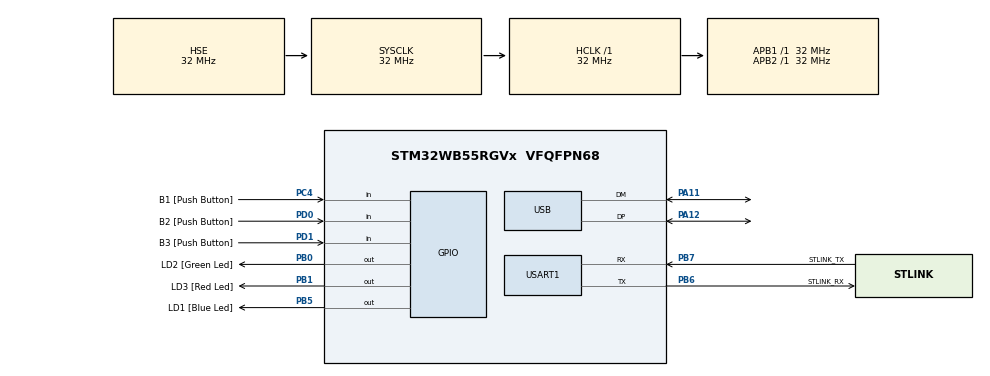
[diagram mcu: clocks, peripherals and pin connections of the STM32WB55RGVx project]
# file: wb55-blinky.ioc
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Mcu.Family=STM32WB
RCC.CortexFreq_Value=32000000
RCC.SMPSCLockSelectionVirtualVirtual=RCC_SMPSCLKSOURCE_HSI
USART1.WordLength=WORDLENGTH_7B
PA14.GPIO_Label=JTCK
PD0.GPIO_Label=B2 [Push Button]
PA11.Mode=Device
PB0.GPIO_Label=LD2 [Green Led]
PB6.GPIO_Label=STLINK_RX
RCC.SYSCLKSource=RCC_SYSCLKSOURCE_HSE
ProjectManager.StackSize=0x400
PA12.Signal=USB_DP
RCC.HCLKFreq_Value=32000000
RCC.APB2TimFreq_Value=32000000
PB6.Signal=USART1_TX
PB6.Mode=Asynchronous
PD0.Signal=GPIO_Input
OSC_OUT.Mode=HSE-External-Oscillator
OSC_OUT.Signal=RCC_OSC_OUT
RCC.AHBFreq_Value=32000000
RCC.HSE_VALUE=32000000
PB3.Mode=Trace_Asynchronous_SW
PD1.GPIO_Label=B3 [Push Button]
PC14-OSC32_IN.Mode=LSE-External-Oscillator
PC4.GPIO_Label=B1 [Push Button]
PA14.Mode=Trace_Asynchronous_SW
PB1.GPIO_Label=LD3 [Red Led]
PB7.Signal=USART1_RX
RCC.APB3Freq_Value=16000000
PB7.GPIO_Label=STLINK_TX
Mcu.Package=VFQFPN68
PB1.Signal=GPIO_Output
PB5.GPIO_Label=LD1 [Blue Led]
RCC.APB1TimFreq_Value=32000000
RCC.SMPSDivider=1
RCC.HSI48_VALUE=48000000
RCC.PLLSAI1N=24
PB3.GPIO_Label=JTDO
PB7.GPIO_PuPd=GPIO_PULLUP
PC15-OSC32_OUT.Mode=LSE-External-Oscillator
PC13.Signal=SYS_WKUP2
PB6.GPIO_PuPd=GPIO_PULLUP
PC4.Signal=GPIO_Input
PD1.Signal=GPIO_Input
PC14-OSC32_IN.Signal=RCC_OSC32_IN
USART1.VirtualMode-Asynchronous=VM_ASYNC
PA13.Signal=SYS_JTMS-SWDIO
ProjectManager.TargetToolchain=SW4STM32
OSC_IN.Signal=RCC_OSC_IN
RCC.USBFreq_Value=48000000
PC15-OSC32_OUT.Signal=RCC_OSC32_OUT
RCC.SMPSCLockSelectionVirtual=RCC_SMPSCLKSOURCE_HSI
board=P-NUCLEO-WB55-Nucleo
RCC.VCOOutputFreq_Value=128000000
RCC.APB2Freq_Value=32000000
RCC.ADCFreq_Value=48000000
PA13.Mode=Trace_Asynchronous_SW
PC13.Mode=SYS_WakeUp1
Mcu.Name=STM32WB55RGVx
PA13.GPIO_Label=JTMS
PB3.Signal=SYS_JTDO-SWO
RCC.SYSCLKFreq_VALUE=32000000
PB5.Signal=GPIO_Output
PA12.Mode=Device
OSC_IN.Mode=HSE-External-Oscillator
PB7.Mode=Asynchronous
PA11.Signal=USB_DM
PA14.Signal=SYS_JTCK-SWCLK
ProjectManager.HeapSize=0x200
RCC.HSI_VALUE=16000000
NVIC.PriorityGroup=NVIC_PRIORITYGROUP_4
RCC.PLLN=32
RCC.APB1Freq_Value=32000000
PB0.Signal=GPIO_Output

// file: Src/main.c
/* USER CODE BEGIN Header */
/**
  ******************************************************************************
  * @file           : main.c
  * @brief          : Main program body
  ******************************************************************************
  * @attention
  *
  * <h2><center>&copy; Copyright (c) 2020 STMicroelectronics.
  * All rights reserved.</center></h2>
  *
  * This software component is licensed by ST under BSD 3-Clause license,
  * the "License"; You may not use this file except in compliance with the
  * License. You may obtain a copy of the License at:
  *                        opensource.org/licenses/BSD-3-Clause
  *
  ******************************************************************************
  */
/* USER CODE END Header */

#include "main.h"

UART_HandleTypeDef huart1;

PCD_HandleTypeDef hpcd_USB_FS;

void SystemClock_Config(void);
static void MX_GPIO_Init(void);
static void MX_USART1_UART_Init(void);
static void MX_USB_PCD_Init(void);

int main(void)
{

  /* MCU Configuration--------------------------------------------------------*/

  /* Reset of all peripherals, Initializes the Flash interface and the Systick. */
  HAL_Init();

  /* Configure the system clock */
  SystemClock_Config();

  /* Initialize all configured peripherals */
  MX_GPIO_Init();
  MX_USART1_UART_Init();
  MX_USB_PCD_Init();

  /* Infinite loop */
  /* USER CODE BEGIN WHILE */
#pragma clang diagnostic push
#pragma ide diagnostic ignored "EndlessLoop"
  while (1)
  {
    HAL_GPIO_WritePin(GPIOB, LD2_Pin, GPIO_PIN_SET);
    HAL_Delay(500);
    HAL_GPIO_WritePin(GPIOB, LD2_Pin, GPIO_PIN_RESET);
    HAL_Delay(500);

    /* USER CODE END WHILE */

    /* USER CODE BEGIN 3 */
  }
#pragma clang diagnostic pop
  /* USER CODE END 3 */
}

void SystemClock_Config(void)
{
  RCC_OscInitTypeDef RCC_OscInitStruct = {0};
  RCC_ClkInitTypeDef RCC_ClkInitStruct = {0};
  RCC_PeriphCLKInitTypeDef PeriphClkInitStruct = {0};

  /** Macro to configure the PLL multiplication factor
  */
  __HAL_RCC_PLL_PLLM_CONFIG(RCC_PLLM_DIV1);
  /** Macro to configure the PLL clock source
  */
  __HAL_RCC_PLL_PLLSOURCE_CONFIG(RCC_PLLSOURCE_MSI);
  /** Configure LSE Drive Capability
  */
  HAL_PWR_EnableBkUpAccess();
  __HAL_RCC_LSEDRIVE_CONFIG(RCC_LSEDRIVE_LOW);
  /** Configure the main internal regulator output voltage
  */
  __HAL_PWR_VOLTAGESCALING_CONFIG(PWR_REGULATOR_VOLTAGE_SCALE1);
  /** Initializes the CPU, AHB and APB busses clocks
  */
  RCC_OscInitStruct.OscillatorType = RCC_OSCILLATORTYPE_HSI|RCC_OSCILLATORTYPE_HSE
                              |RCC_OSCILLATORTYPE_LSE|RCC_OSCILLATORTYPE_MSI;
  RCC_OscInitStruct.HSEState = RCC_HSE_ON;
  RCC_OscInitStruct.LSEState = RCC_LSE_ON;
  RCC_OscInitStruct.HSIState = RCC_HSI_ON;
  RCC_OscInitStruct.MSIState = RCC_MSI_ON;
  RCC_OscInitStruct.HSICalibrationValue = RCC_HSICALIBRATION_DEFAULT;
  RCC_OscInitStruct.MSICalibrationValue = RCC_MSICALIBRATION_DEFAULT;
  RCC_OscInitStruct.MSIClockRange = RCC_MSIRANGE_6;
  RCC_OscInitStruct.PLL.PLLState = RCC_PLL_NONE;
  if (HAL_RCC_OscConfig(&RCC_OscInitStruct) != HAL_OK)
  {
    Error_Handler();
  }
  /** Configure the SYSCLKSource, HCLK, PCLK1 and PCLK2 clocks dividers
  */
  RCC_ClkInitStruct.ClockType = RCC_CLOCKTYPE_HCLK4|RCC_CLOCKTYPE_HCLK2
                              |RCC_CLOCKTYPE_HCLK|RCC_CLOCKTYPE_SYSCLK
                              |RCC_CLOCKTYPE_PCLK1|RCC_CLOCKTYPE_PCLK2;
  RCC_ClkInitStruct.SYSCLKSource = RCC_SYSCLKSOURCE_HSE;
  RCC_ClkInitStruct.AHBCLKDivider = RCC_SYSCLK_DIV1;
  RCC_ClkInitStruct.APB1CLKDivider = RCC_HCLK_DIV1;
  RCC_ClkInitStruct.APB2CLKDivider = RCC_HCLK_DIV1;
  RCC_ClkInitStruct.AHBCLK2Divider = RCC_SYSCLK_DIV1;
  RCC_ClkInitStruct.AHBCLK4Divider = RCC_SYSCLK_DIV1;

  if (HAL_RCC_ClockConfig(&RCC_ClkInitStruct, FLASH_LATENCY_1) != HAL_OK)
  {
    Error_Handler();
  }
  /** Initializes the peripherals clocks
  */
  PeriphClkInitStruct.PeriphClockSelection = RCC_PERIPHCLK_SMPS|RCC_PERIPHCLK_USART1
                              |RCC_PERIPHCLK_USB;
  PeriphClkInitStruct.PLLSAI1.PLLN = 24;
  PeriphClkInitStruct.PLLSAI1.PLLP = RCC_PLLP_DIV2;
  PeriphClkInitStruct.PLLSAI1.PLLQ = RCC_PLLQ_DIV2;
  PeriphClkInitStruct.PLLSAI1.PLLR = RCC_PLLR_DIV2;
  PeriphClkInitStruct.PLLSAI1.PLLSAI1ClockOut = RCC_PLLSAI1_USBCLK;
  PeriphClkInitStruct.Usart1ClockSelection = RCC_USART1CLKSOURCE_PCLK2;
  PeriphClkInitStruct.UsbClockSelection = RCC_USBCLKSOURCE_PLLSAI1;
  PeriphClkInitStruct.SmpsClockSelection = RCC_SMPSCLKSOURCE_HSI;
  PeriphClkInitStruct.SmpsDivSelection = RCC_SMPSCLKDIV_RANGE0;
  if (HAL_RCCEx_PeriphCLKConfig(&PeriphClkInitStruct) != HAL_OK)
  {
    Error_Handler();
  }
  /** Enable MSI Auto calibration
  */
  HAL_RCCEx_EnableMSIPLLMode();
}

static void MX_USART1_UART_Init(void)
{

  huart1.Instance = USART1;
  huart1.Init.BaudRate = 115200;
  huart1.Init.WordLength = UART_WORDLENGTH_7B;
  huart1.Init.StopBits = UART_STOPBITS_1;
  huart1.Init.Parity = UART_PARITY_NONE;
  huart1.Init.Mode = UART_MODE_TX_RX;
  huart1.Init.HwFlowCtl = UART_HWCONTROL_NONE;
  huart1.Init.OverSampling = UART_OVERSAMPLING_16;
  huart1.Init.OneBitSampling = UART_ONE_BIT_SAMPLE_DISABLE;
  huart1.Init.ClockPrescaler = UART_PRESCALER_DIV1;
  huart1.AdvancedInit.AdvFeatureInit = UART_ADVFEATURE_NO_INIT;
  if (HAL_UART_Init(&huart1) != HAL_OK)
  {
    Error_Handler();
  }
  if (HAL_UARTEx_SetTxFifoThreshold(&huart1, UART_TXFIFO_THRESHOLD_1_8) != HAL_OK)
  {
    Error_Handler();
  }
  if (HAL_UARTEx_SetRxFifoThreshold(&huart1, UART_RXFIFO_THRESHOLD_1_8) != HAL_OK)
  {
    Error_Handler();
  }
  if (HAL_UARTEx_DisableFifoMode(&huart1) != HAL_OK)
  {
    Error_Handler();
  }

}

static void MX_USB_PCD_Init(void)
{

  hpcd_USB_FS.Instance = USB;
  hpcd_USB_FS.Init.dev_endpoints = 8;
  hpcd_USB_FS.Init.speed = PCD_SPEED_FULL;
  hpcd_USB_FS.Init.phy_itface = PCD_PHY_EMBEDDED;
  hpcd_USB_FS.Init.Sof_enable = DISABLE;
  hpcd_USB_FS.Init.low_power_enable = DISABLE;
  hpcd_USB_FS.Init.lpm_enable = DISABLE;
  hpcd_USB_FS.Init.battery_charging_enable = DISABLE;
  if (HAL_PCD_Init(&hpcd_USB_FS) != HAL_OK)
  {
    Error_Handler();
  }

}

static void MX_GPIO_Init(void)
{
  GPIO_InitTypeDef GPIO_InitStruct = {0};

  /* GPIO Ports Clock Enable */
  __HAL_RCC_GPIOC_CLK_ENABLE();
  __HAL_RCC_GPIOB_CLK_ENABLE();
  __HAL_RCC_GPIOA_CLK_ENABLE();
  __HAL_RCC_GPIOD_CLK_ENABLE();

  /*Configure GPIO pin Output Level */
  HAL_GPIO_WritePin(GPIOB, LD2_Pin|LD3_Pin|LD1_Pin, GPIO_PIN_RESET);

  /*Configure GPIO pin : B1_Pin */
  GPIO_InitStruct.Pin = B1_Pin;
  GPIO_InitStruct.Mode = GPIO_MODE_INPUT;
  GPIO_InitStruct.Pull = GPIO_NOPULL;
  HAL_GPIO_Init(B1_GPIO_Port, &GPIO_InitStruct);

  /*Configure GPIO pins : LD2_Pin LD3_Pin LD1_Pin */
  GPIO_InitStruct.Pin = LD2_Pin|LD3_Pin|LD1_Pin;
  GPIO_InitStruct.Mode = GPIO_MODE_OUTPUT_PP;
  GPIO_InitStruct.Pull = GPIO_NOPULL;
  GPIO_InitStruct.Speed = GPIO_SPEED_FREQ_LOW;
  HAL_GPIO_Init(GPIOB, &GPIO_InitStruct);

  /*Configure GPIO pins : B2_Pin B3_Pin */
  GPIO_InitStruct.Pin = B2_Pin|B3_Pin;
  GPIO_InitStruct.Mode = GPIO_MODE_INPUT;
  GPIO_InitStruct.Pull = GPIO_NOPULL;
  HAL_GPIO_Init(GPIOD, &GPIO_InitStruct);

}

void Error_Handler(void)
{
}

/************************ (C) COPYRIGHT STMicroelectronics *****END OF FILE****/
